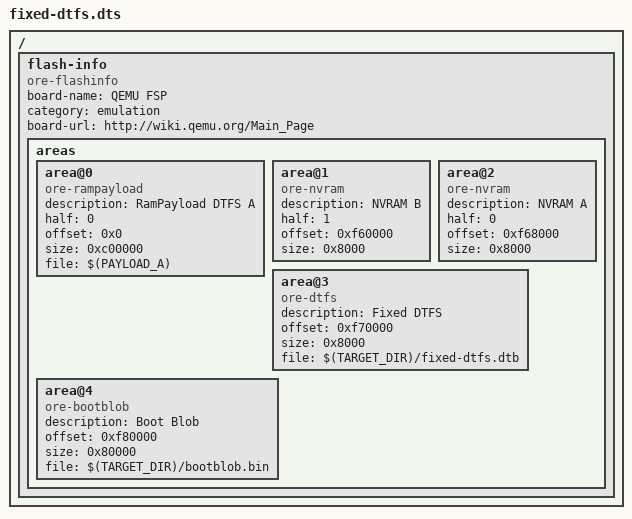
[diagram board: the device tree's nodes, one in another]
/dts-v1/;

/ {
    #address-cells = <1>;
    #size-cells = <1>;

    flash-info {
        compatible = "ore-flashinfo";
        board-name = "QEMU FSP";
        category = "emulation";
        board-url = "http://wiki.qemu.org/Main_Page";
        areas {
            area@0 {
                description = "RamPayload DTFS A";
                compatible = "ore-rampayload";
                half = <0>;
                offset = <0x0>;
                size = <0xc00000>;
                file = "$(PAYLOAD_A)";
            };
            area@1 {
                description = "NVRAM B";
                compatible = "ore-nvram";
                half = <1>;
                offset = <0xf60000>;
                size = <0x8000>;
            };
            area@2 {
                description = "NVRAM A";
                compatible = "ore-nvram";
                half = <0>;
                offset = <0xf68000>;
                size = <0x8000>;
            };
            area@3 {
                description = "Fixed DTFS";
                compatible = "ore-dtfs";
                offset = <0xf70000>;
                size = <0x8000>;
                file = "$(TARGET_DIR)/fixed-dtfs.dtb";
            };
            area@4 {
                description = "Boot Blob";
                compatible = "ore-bootblob";
                offset = <0xf80000>;
                size = <0x80000>;
                file = "$(TARGET_DIR)/bootblob.bin";
            };
        };
    };
};
